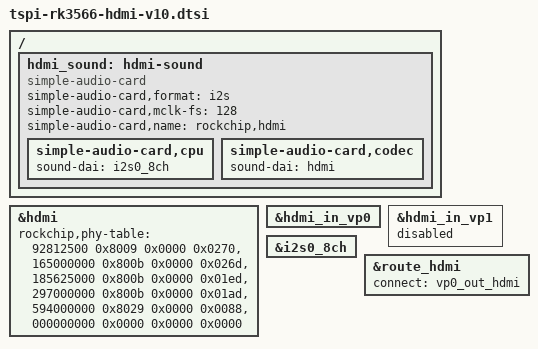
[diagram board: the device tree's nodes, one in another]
// SPDX-License-Identifier: (GPL-2.0+ OR MIT)
/*
 * Copyright (c) 2020 Rockchip Electronics Co., Ltd.
 *
 */

/{
    hdmi_sound: hdmi-sound {
		compatible = "simple-audio-card";
		simple-audio-card,format = "i2s";
		simple-audio-card,mclk-fs = <128>;
		simple-audio-card,name = "rockchip,hdmi";
		status = "disabled";

		simple-audio-card,cpu {
				sound-dai = <&i2s0_8ch>;
		};
		simple-audio-card,codec {
				sound-dai = <&hdmi>;
		};
	};
};

&hdmi {
	status = "okay";
	rockchip,phy-table =
		<92812500  0x8009 0x0000 0x0270>,
		<165000000 0x800b 0x0000 0x026d>,
		<185625000 0x800b 0x0000 0x01ed>,
		<297000000 0x800b 0x0000 0x01ad>,
		<594000000 0x8029 0x0000 0x0088>,
		<000000000 0x0000 0x0000 0x0000>;
};

&hdmi_in_vp0 {
	status = "okay";
};

&hdmi_in_vp1 {
	status = "disabled";
};

&hdmi_sound {
	status = "okay";
};

&i2s0_8ch {
	status = "okay";
};

&route_hdmi {
	status = "okay";
	connect = <&vp0_out_hdmi>;
};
